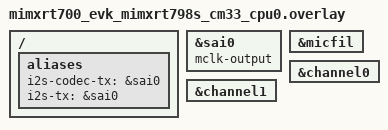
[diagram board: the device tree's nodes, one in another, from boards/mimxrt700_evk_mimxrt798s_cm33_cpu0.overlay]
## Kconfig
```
# Copyright (c) 2024 NXP
# SPDX-License-Identifier: Apache-2.0

source "Kconfig.zephyr"

config I2S_INIT_BUFFERS
	int "Initial count of audio data blocks"
	default 4
	help
	  Controls the initial count of audio data blocks, which are (optionally)
	  filled by data from the DMIC peripheral and played back by the I2S
	  output peripheral.

config SAMPLE_FREQ
	int "Sample rate"
	default 16000
	help
	  Sample frequency of the system.

config SAMPLE_USE_CODEC_CLOCK
	bool "I2S BCK is generated by a selected codec device"
	help
	  If selected, the I2S selected peripheral will be configured to consume
	  (receive) the I2S BCK and WS signals and the codec will be configured
	  to generate those. If not selected, the I2S peripheral will generate
	  them and the codec will be expected to consume them.

config EXTRA_BLOCKS
	int "Number of extra blocks"
	default 32
	help
	  Extra blocks for storing PCM sample.

config SAMPLE_WIDTH
	int "Sample bit width"
	default 16
	help
	  PCM sample bit width.

config BYTES_PER_SAMPLE
	int "Bytes per sample"
	default 2
	help
	  Number of bytes per PCM sample.

config USE_DMIC
	bool "Use DMIC as an audio input"

if USE_DMIC

config DMIC_CHANNELS
	int "Number of DMIC channels"
	default 1
	help
	  Count of DMIC channels to capture and process.

endif
```

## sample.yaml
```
sample:
  name: codec sample
tests:
  sample.drivers.i2s.codec:
    tags: i2s
    platform_allow:
      - mimxrt595_evk/mimxrt595s/cm33
      - mimxrt1170_evk@B/mimxrt1176/cm7
      - mimxrt700_evk/mimxrt798s/cm33_cpu0
      - mimxrt1060_evk/mimxrt1062/qspi
      - mimxrt1180_evk/mimxrt1189/cm33
      - mimxrt1180_evk/mimxrt1189/cm7
      - frdm_mcxn236
      - mcx_n5xx_evk/mcxn547/cpu0
    harness: console
    harness_config:
      type: one_line
      regex:
        - "start streams"
```

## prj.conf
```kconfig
CONFIG_I2S=y
CONFIG_AUDIO=y
CONFIG_AUDIO_DMIC=y
CONFIG_AUDIO_CODEC=y
CONFIG_NO_OPTIMIZATIONS=y
CONFIG_MAIN_STACK_SIZE=8192
CONFIG_SYSTEM_WORKQUEUE_STACK_SIZE=8192
CONFIG_ISR_STACK_SIZE=8192

CONFIG_DEBUG_THREAD_INFO=y

CONFIG_LOG=y
CONFIG_LOG_DEFAULT_LEVEL=4
CONFIG_SERIAL=y
CONFIG_UART_CONSOLE=y
CONFIG_CONSOLE=y
CONFIG_LOG_BUFFER_SIZE=10240

CONFIG_MPU=n
CONFIG_ARM_MPU=n
CONFIG_HW_STACK_PROTECTION=n
```

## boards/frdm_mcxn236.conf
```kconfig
# Copyright 2025 NXP
#
# SPDX-License-Identifier: Apache-2.0

CONFIG_DMA_TCD_QUEUE_SIZE=4
CONFIG_SAMPLE_FREQ=16000
CONFIG_I2S_INIT_BUFFERS=1
CONFIG_SAMPLE_USE_CODEC_CLOCK=y
CONFIG_USE_DMIC=y
CONFIG_DMIC_CHANNELS=1
CONFIG_EXTRA_BLOCKS=10
CONFIG_SAMPLE_WIDTH=32
CONFIG_BYTES_PER_SAMPLE=4
```

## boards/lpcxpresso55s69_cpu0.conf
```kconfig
#
# Copyright 2025 NXP
#
# SPDX-License-Identifier: Apache-2.0
#

CONFIG_DMA=y
CONFIG_USE_DMIC=n

CONFIG_CODEC_MASTER=y
CONFIG_I2S_MASTER=n

# Sample rate decreased because of memory size
CONFIG_SAMPLE_FREQ=8000
```

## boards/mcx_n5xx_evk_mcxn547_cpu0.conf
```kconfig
# Copyright 2025 NXP
#
# SPDX-License-Identifier: Apache-2.0

CONFIG_DMA_TCD_QUEUE_SIZE=4
CONFIG_SAMPLE_FREQ=16000
CONFIG_I2S_INIT_BUFFERS=1
CONFIG_SAMPLE_USE_CODEC_CLOCK=y
CONFIG_USE_DMIC=y
CONFIG_DMIC_CHANNELS=2
CONFIG_EXTRA_BLOCKS=10
CONFIG_SAMPLE_WIDTH=32
CONFIG_BYTES_PER_SAMPLE=4
```

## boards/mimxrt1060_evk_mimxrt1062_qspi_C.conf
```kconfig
#
# Copyright 2025 NXP
#
# SPDX-License-Identifier: Apache-2.0
#

CONFIG_HEAP_MEM_POOL_SIZE=81920
CONFIG_AUDIO_CODEC=y
CONFIG_DMA_TCD_QUEUE_SIZE=4
CONFIG_SAMPLE_FREQ=16000
CONFIG_USE_DMIC=n
CONFIG_CODEC_MASTER=n
CONFIG_I2S_MASTER=y
```

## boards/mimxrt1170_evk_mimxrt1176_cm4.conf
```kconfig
#
# Copyright 2025 NXP
#
# SPDX-License-Identifier: Apache-2.0
#

CONFIG_AUDIO=y
CONFIG_DMA_TCD_QUEUE_SIZE=4
CONFIG_USE_DMIC=n
CONFIG_CODEC_MASTER=n
CONFIG_I2S_MASTER=y

# Sample rate decreased because of available memory
CONFIG_SAMPLE_FREQ=4000
```

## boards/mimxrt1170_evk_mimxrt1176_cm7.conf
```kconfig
#
# Copyright 2026 NXP
#
# SPDX-License-Identifier: Apache-2.0
#

CONFIG_DMA_TCD_QUEUE_SIZE=4
CONFIG_I3C=y
CONFIG_I2S_INIT_BUFFERS=2
CONFIG_USE_DMIC=y
CONFIG_DMIC_CHANNELS=2
CONFIG_EXTRA_BLOCKS=2
CONFIG_SAMPLE_WIDTH=32
CONFIG_BYTES_PER_SAMPLE=4
```

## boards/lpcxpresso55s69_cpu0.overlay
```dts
/*
 * Copyright 2025 NXP
 *
 * SPDX-License-Identifier: Apache-2.0
 */

/ {
    aliases {
        i2s-codec-rx = &flexcomm6;
        i2s-codec-tx = &flexcomm7;
    };
};
```

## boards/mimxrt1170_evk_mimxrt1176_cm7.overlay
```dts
/*
 * Copyright 2025 NXP
 *
 * SPDX-License-Identifier: Apache-2.0
 */

&sai1 {
	mclk-output;
};

dmic_dev: &dmic {
	status = "okay";
};

&gpio6 {
	status = "disabled";
};

&gpio12 {
	status = "disabled";
};
```

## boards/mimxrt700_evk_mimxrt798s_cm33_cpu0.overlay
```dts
/*
 * Copyright 2025 NXP
 *
 * SPDX-License-Identifier: Apache-2.0
 */

/ {
	aliases {
		i2s-codec-tx = &sai0;
		i2s-tx = &sai0;
	};
};

&sai0 {
	mclk-output;
};

dmic_dev: &micfil {
	status = "okay";
};

&channel0 {
	status = "okay";
};

&channel1 {
	status = "okay";
};
```

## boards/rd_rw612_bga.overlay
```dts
/*
 * Copyright 2025 NXP
 *
 * SPDX-License-Identifier: Apache-2.0
 */

/ {
    aliases {
        i2s-codec-tx = &flexcomm1;
    };
};

&flexcomm1 {
    #address-cells = <1>;
	#size-cells = <0>;
    
    compatible = "nxp,lpc-i2s";
	
	pinctrl-0 = <&pinmux_flexcomm1_i2s>;
	pinctrl-names = "default";

	status = "okay";
};

dmic_dev: &dmic0 {
	status = "okay";
};
```

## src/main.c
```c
/*
 * Copyright 2024-2025 NXP
 *
 * SPDX-License-Identifier: Apache-2.0
 */

#include <zephyr/kernel.h>
#include <zephyr/sys/printk.h>
#include <zephyr/audio/dmic.h>
#include <zephyr/drivers/i2s.h>
#include <zephyr/audio/codec.h>
#include <zephyr/toolchain.h>
#include <string.h>

#ifndef CONFIG_USE_DMIC
#include "sine.h"
#endif

#define I2S_CODEC_TX DT_ALIAS(i2s_codec_tx)

#define SAMPLE_FREQUENCY CONFIG_SAMPLE_FREQ
#define SAMPLE_BIT_WIDTH CONFIG_SAMPLE_WIDTH
#define BYTES_PER_SAMPLE CONFIG_BYTES_PER_SAMPLE
#if CONFIG_USE_DMIC
#define NUMBER_OF_CHANNELS CONFIG_DMIC_CHANNELS
#else
#define NUMBER_OF_CHANNELS (2U)
#endif
/* Such block length provides an echo with the delay of 100 ms. */
#define SAMPLES_PER_BLOCK ((SAMPLE_FREQUENCY / 10) * NUMBER_OF_CHANNELS)
#define INITIAL_BLOCKS    CONFIG_I2S_INIT_BUFFERS
#define TIMEOUT           (2000U)

#define BLOCK_SIZE  (BYTES_PER_SAMPLE * SAMPLES_PER_BLOCK)
#define BLOCK_COUNT (INITIAL_BLOCKS + CONFIG_EXTRA_BLOCKS)

K_MEM_SLAB_DEFINE_IN_SECT_STATIC(mem_slab, __nocache, BLOCK_SIZE, BLOCK_COUNT, 4);

static bool configure_tx_streams(const struct device *i2s_dev, struct i2s_config *config)
{
	int ret;

	ret = i2s_configure(i2s_dev, I2S_DIR_TX, config);
	if (ret < 0) {
		printk("Failed to configure codec stream: %d\n", ret);
		return false;
	}

	return true;
}

static bool trigger_command(const struct device *i2s_dev_codec, enum i2s_trigger_cmd cmd)
{
	int ret;

	ret = i2s_trigger(i2s_dev_codec, I2S_DIR_TX, cmd);
	if (ret < 0) {
		printk("Failed to trigger command %d on TX: %d\n", cmd, ret);
		return false;
	}

	return true;
}

int main(void)
{
	const struct device *const i2s_dev_codec = DEVICE_DT_GET(I2S_CODEC_TX);
#if CONFIG_USE_DMIC
	const struct device *const dmic_dev = DEVICE_DT_GET(DT_NODELABEL(dmic_dev));
#endif
	const struct device *const codec_dev = DEVICE_DT_GET(DT_NODELABEL(audio_codec));
	struct i2s_config config;
	struct audio_codec_cfg audio_cfg;
	int ret = 0;

#if CONFIG_USE_DMIC
	struct pcm_stream_cfg stream = {
		.pcm_width = SAMPLE_BIT_WIDTH,
		.mem_slab = &mem_slab,
	};
	struct dmic_cfg cfg = {
		.io = {
			/* These fields can be used to limit the PDM clock
			 * configurations that the driver is allowed to use
			 * to those supported by the microphone.
			 */
			.min_pdm_clk_freq = 1000000,
			.max_pdm_clk_freq = 3500000,
			.min_pdm_clk_dc   = 40,
			.max_pdm_clk_dc   = 60,
		},
		.streams = &stream,
		.channel = {
			.req_num_streams = 1,
		},
	};
#endif
	printk("codec sample\n");

#if CONFIG_USE_DMIC
	if (!device_is_ready(dmic_dev)) {
		printk("%s is not ready", dmic_dev->name);
		return 0;
	}
#endif

	if (!device_is_ready(i2s_dev_codec)) {
		printk("%s is not ready\n", i2s_dev_codec->name);
		return 0;
	}

	if (!device_is_ready(codec_dev)) {
		printk("%s is not ready", codec_dev->name);
		return 0;
	}
	audio_cfg.dai_route = AUDIO_ROUTE_PLAYBACK;
	audio_cfg.dai_type = AUDIO_DAI_TYPE_I2S;
	audio_cfg.dai_cfg.i2s.word_size = SAMPLE_BIT_WIDTH;
	audio_cfg.dai_cfg.i2s.channels = 2;
	audio_cfg.dai_cfg.i2s.format = I2S_FMT_DATA_FORMAT_I2S;
#ifdef CONFIG_SAMPLE_USE_CODEC_CLOCK
	audio_cfg.dai_cfg.i2s.options = I2S_OPT_FRAME_CLK_CONTROLLER |
					 I2S_OPT_BIT_CLK_CONTROLLER;
#else
	audio_cfg.dai_cfg.i2s.options = I2S_OPT_FRAME_CLK_TARGET |
					 I2S_OPT_BIT_CLK_TARGET;
#endif
	audio_cfg.dai_cfg.i2s.frame_clk_freq = SAMPLE_FREQUENCY;
	audio_cfg.dai_cfg.i2s.mem_slab = &mem_slab;
	audio_cfg.dai_cfg.i2s.block_size = BLOCK_SIZE;
	ret = audio_codec_configure(codec_dev, &audio_cfg);
	if (ret < 0) {
		printk("Failed to configure codec: %d\n", ret);
		return ret;
	}
	k_msleep(1000);

#if CONFIG_USE_DMIC
	cfg.channel.req_num_chan = 2;
	cfg.channel.req_chan_map_lo = dmic_build_channel_map(0, 0, PDM_CHAN_LEFT) |
				      dmic_build_channel_map(1, 0, PDM_CHAN_RIGHT);
	cfg.streams[0].pcm_rate = SAMPLE_FREQUENCY;
	cfg.streams[0].block_size = BLOCK_SIZE;

	printk("PCM output rate: %u, channels: %u\n", cfg.streams[0].pcm_rate,
	       cfg.channel.req_num_chan);

	ret = dmic_configure(dmic_dev, &cfg);
	if (ret < 0) {
		printk("Failed to configure the driver: %d", ret);
		return ret;
	}
#endif

	config.word_size = SAMPLE_BIT_WIDTH;
	config.channels = NUMBER_OF_CHANNELS;
	config.format = I2S_FMT_DATA_FORMAT_I2S;
#ifdef CONFIG_SAMPLE_USE_CODEC_CLOCK
	config.options = I2S_OPT_BIT_CLK_TARGET | I2S_OPT_FRAME_CLK_TARGET;
#else
	config.options = I2S_OPT_BIT_CLK_CONTROLLER | I2S_OPT_FRAME_CLK_CONTROLLER;
#endif
	config.frame_clk_freq = SAMPLE_FREQUENCY;
	config.mem_slab = &mem_slab;
	config.block_size = BLOCK_SIZE;
	config.timeout = TIMEOUT;
	if (!configure_tx_streams(i2s_dev_codec, &config)) {
		printk("failure to config streams\n");
		return 0;
	}

	printk("start streams\n");
	for (;;) {
		bool started = false;
#if CONFIG_USE_DMIC
		ret = dmic_trigger(dmic_dev, DMIC_TRIGGER_START);
		if (ret < 0) {
			printk("START trigger failed: %d", ret);
			return ret;
		}
#endif
		while (1) {
			void *mem_block;
			uint32_t block_size = BLOCK_SIZE;
			int i;

			for (i = 0; i < CONFIG_I2S_INIT_BUFFERS; i++) {
#if CONFIG_USE_DMIC
				/* If using DMIC, use a buffer (memory slab) from dmic_read */
				ret = dmic_read(dmic_dev, 0, &mem_block, &block_size, TIMEOUT);
				if (ret < 0) {
					printk("read failed: %d", ret);
					break;
				}

				ret = i2s_write(i2s_dev_codec, mem_block, block_size);
#else
				/* If not using DMIC, play a sine wave 440Hz */

				BUILD_ASSERT(
					BLOCK_SIZE <= __16kHz16bit_stereo_sine_pcm_len,
					"BLOCK_SIZE is bigger than test sine wave buffer size."
				);
				mem_block = (void *)&__16kHz16bit_stereo_sine_pcm;

				ret = i2s_buf_write(i2s_dev_codec, mem_block, block_size);
#endif
				if (ret < 0) {
					printk("Failed to write data: %d\n", ret);
					break;
				}
			}
			if (ret < 0) {
				printk("error %d\n", ret);
				break;
			}
			if (!started) {
				i2s_trigger(i2s_dev_codec, I2S_DIR_TX, I2S_TRIGGER_START);
				started = true;
			}
		}
		if (!trigger_command(i2s_dev_codec, I2S_TRIGGER_DROP)) {
			printk("Send I2S trigger DRAIN failed: %d", ret);
			return 0;
		}
#if CONFIG_USE_DMIC
		ret = dmic_trigger(dmic_dev, DMIC_TRIGGER_STOP);
		if (ret < 0) {
			printk("STOP trigger failed: %d", ret);
			return 0;
		}
#endif
		printk("Streams stopped\n");
		return 0;
	}
}
```
